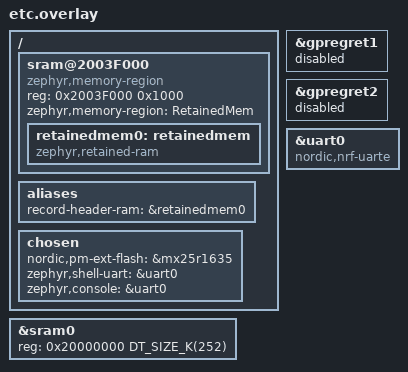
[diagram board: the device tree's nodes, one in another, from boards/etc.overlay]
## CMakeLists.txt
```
# SPDX-License-Identifier: Apache-2.0

cmake_minimum_required(VERSION 3.20.0)

find_package(Zephyr REQUIRED HINTS $ENV{ZEPHYR_BASE})
project(etc-retain)

FILE(GLOB app_sources src/*.c)
target_sources(app PRIVATE ${app_sources})
```

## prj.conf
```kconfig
CONFIG_STDOUT_CONSOLE=y
CONFIG_LOG=y
CONFIG_LOG_BUFFER_SIZE=4096
CONFIG_SERIAL=y

# Retain memory
CONFIG_RETAINED_MEM=y
CONFIG_RETAINED_MEM_NRF_GPREGRET=n
CONFIG_SHELL=y
```

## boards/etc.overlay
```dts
/ {
	sram@2003F000 {
		compatible = "zephyr,memory-region", "mmio-sram";
		reg = <0x2003F000 0x1000>;
		zephyr,memory-region = "RetainedMem";
		status = "okay";

		retainedmem0: retainedmem {
			compatible = "zephyr,retained-ram";
			status = "okay";
	        };
        };

	aliases {
		record-header-ram = &retainedmem0;
	};
};

&gpregret1 {
	status = "disabled";
};

&gpregret2 {
	status = "disabled";
};

&sram0 {
	reg = <0x20000000 DT_SIZE_K(252)>;
};

/ {
	chosen {
		nordic,pm-ext-flash = &mx25r1635;
		zephyr,shell-uart = &uart0;
		zephyr,console = &uart0;
	};
};

&uart0 {
	compatible = "nordic,nrf-uarte";
	status = "okay";
};
```

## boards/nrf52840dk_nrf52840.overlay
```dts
/ {
	sram@2003F000 {
		compatible = "zephyr,memory-region", "mmio-sram";
		reg = <0x2003F000 0x1000>;
		zephyr,memory-region = "RetainedMem";
		status = "okay";

		retainedmem0: retainedmem {
			compatible = "zephyr,retained-ram";
			status = "okay";
	        };
        };

	aliases {
		record-header-ram = &retainedmem0;
	};
};

&gpregret1 {
	status = "disabled";
};

&gpregret2 {
	status = "disabled";
};

&sram0 {
	reg = <0x20000000 DT_SIZE_K(252)>;
};
```

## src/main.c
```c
#include <stdio.h>
#include <string.h>
#include <zephyr/device.h>
#include <zephyr/drivers/uart.h>
#include <zephyr/drivers/gpio.h>
#include <zephyr/kernel.h>
#include <zephyr/usb/usb_device.h>
#include <zephyr/logging/log.h>
#include <zephyr/drivers/retained_mem.h>
#include <zephyr/shell/shell.h>
LOG_MODULE_REGISTER(main, LOG_LEVEL_INF);

#include "etc_device.h"
#include "etc_device_record.h"

int main(void)
{
	etc_device_record_init();
	etc_device_init();
	return 0;
}

static int cmd_write_record(const struct shell *shell, size_t argc, char **argv)
{
	if (argc == 2) {
		int num_of_sample = atoi(argv[1]);
		for (int i = 0; i < num_of_sample; i++) {
			etc_device_write();
		}
	} else {
		shell_error(shell, "Invalid input parameter for generating record");
	}

	return 0;
}

static int cmd_read_record(const struct shell *shell, size_t argc, char **argv)
{
	if (argc == 2) {
		int num_of_sample = atoi(argv[1]);
		for (int i = 0; i < num_of_sample; i++) {
			etc_device_read();
		}
	}
	return 0;
}

static int cmd_report_record(const struct shell *shell, size_t argc, char **argv)
{
	etc_device_report(shell);
	return 0;
}

static int cmd_export_record(const struct shell *shell, size_t argc, char **argv)
{
	etc_device_export_old_structure(shell);
	return 0;
}

static int cmd_dump_record(const struct shell *shell, size_t argc, char **argv)
{
	uint8_t* record = etc_device_record_dump();
	shell_hexdump(shell, record, ETC_DEVICE_RECORD_BUF_SIZE);
	return 0;
}

static int cmd_dump_old_record(const struct shell *shell, size_t argc, char **argv)
{
	uint8_t* record = etc_device_dump();
	shell_hexdump(shell, record, MAX_RECORD_NO_OFFSET_ID);
	return 0;
}

static int cmd_clean_record(const struct shell *shell, size_t argc, char **argv)
{
	etc_device_record_clean_up();
	return 0;
}

SHELL_STATIC_SUBCMD_SET_CREATE(
	sub_record,
	SHELL_CMD(write, NULL, "Init", cmd_write_record),
	SHELL_CMD(read, NULL, "Read", cmd_read_record),
	SHELL_CMD(report, NULL, "Report", cmd_report_record),
	SHELL_CMD(export, NULL, "Export", cmd_export_record),
	SHELL_CMD(dump, NULL, "Dump", cmd_dump_record),
	SHELL_CMD(dump_old, NULL, "Dump Old", cmd_dump_old_record),
	SHELL_CMD(clean, NULL, "Clean", cmd_clean_record),
	SHELL_SUBCMD_SET_END);
SHELL_CMD_REGISTER(record, &sub_record, "ETC Record Management", NULL);
```

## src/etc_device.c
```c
#include <stdio.h>
#include <string.h>
#include <zephyr/device.h>
#include <zephyr/logging/log.h>
#include <zephyr/shell/shell.h>
LOG_MODULE_REGISTER(etc_device, LOG_LEVEL_DBG);

#include "etc_device.h"
#include "etc_device_record.h"
#define OLD_RECORD 1

struct etc_device_record_table *etc_device_record_table = &etc_device_record.record_stat;

uint8_t record_header[MAX_RECORD_ID];
static uint16_t ram_nack_record_id;

void etc_device_init(void) {
	memset(record_header, 0, MAX_RECORD_ID);
	ram_nack_record_id = 0;
}

static struct etc_device_record_index etc_device_get_next_index(void)
{
	if (etc_device_record_table->newest.element_idx < ETC_RECORD_MAX_PER_SECTOR - 1) {
		etc_device_record_table->newest.element_idx += 1;
	} else {
		etc_device_record_table->newest.element_idx = 0;
		if (etc_device_record_table->newest.sector_idx < ETC_RECORD_MAX_SECTOR - 1) {
			etc_device_record_table->newest.sector_idx += 1;
		} else {
			etc_device_record_table->newest.sector_idx = 0;
		}
	}

	if (etc_device_record_table->total < ETC_RECORD_MAX_RECORD) {
		etc_device_record_table->oldest.element_idx = 0;
		etc_device_record_table->oldest.sector_idx = 0;
		etc_device_record_table->total += 1;
	} else {
		if (etc_device_record_table->oldest.element_idx < ETC_RECORD_MAX_PER_SECTOR - 1) {
			etc_device_record_table->oldest.element_idx += 1;
		} else {
			etc_device_record_table->oldest.element_idx = 0;
			if (etc_device_record_table->oldest.sector_idx < ETC_RECORD_MAX_SECTOR - 1) {
				etc_device_record_table->oldest.sector_idx += 1;
			} else {
				etc_device_record_table->oldest.sector_idx = 0;
			}
		}
	}

	return etc_device_record_table->newest;
}

struct etc_device_record_index etc_device_write(void) {
	struct etc_device_record_index record_index;
	if (etc_device_record_table->total == 0) {
		record_index = etc_device_record_table->newest;
		etc_device_record_table->total += 1;
	} else {
		record_index = etc_device_get_next_index();
	}

	uint16_t record_id = record_index.sector_idx * ETC_RECORD_MAX_PER_SECTOR +
			     record_index.element_idx;
	#if OLD_RECORD
	record_header[ETC_RECORD_ID_HEADER(record_id)] = 0U;
	#else
	etc_device_record_set_nack(record_id);
	#endif
	etc_device_record_save_stat();
	return record_index;
}

int etc_device_find_nack(void)
{
	int rc = 0;
	int newest_id = etc_device_record_table->newest.sector_idx * ETC_RECORD_MAX_PER_SECTOR +
			etc_device_record_table->newest.element_idx + ETC_RECORD_HEADER;
	int oldest_id = etc_device_record_table->oldest.sector_idx * ETC_RECORD_MAX_PER_SECTOR +
			etc_device_record_table->oldest.element_idx + ETC_RECORD_HEADER;
	uint16_t max_id = ETC_RECORD_MAX_SECTOR * ETC_RECORD_MAX_PER_SECTOR + ETC_RECORD_HEADER - 1;
	uint16_t min_id = ETC_RECORD_HEADER;
	uint16_t last_id = ram_nack_record_id;
	uint16_t check_id = 0;
	bool find_next = false;

	if (last_id == newest_id) {
		return 0;
	}

	check_id = last_id == 0 ? oldest_id : last_id + 1;
	if (check_id > max_id) {
		check_id = min_id;
	}

next_id:
	// LOG_DBG("Last ID %u - Check ID %d - New ID %d", last_id, check_id, newest_id);

	if (record_header[check_id] == 0) {
		rc = check_id;
	} else {
		find_next = true;
	}

	if (find_next) {
		find_next = false;
		if (newest_id != check_id) {
			/* Increase the ram_nack_record_id */
			check_id += 1;
			if (check_id > max_id) {
				check_id = min_id;
			}
			goto next_id;
		} 
	}

	return rc;
}

void etc_device_read(void) {
	int rc = etc_device_find_nack();
	if (rc == 0) {
		LOG_WRN("No more NACK");
		return;
	}
	// LOG_DBG("Record %d", rc);
	ram_nack_record_id = rc;
	record_header[rc] = 1U;
}

uint16_t etc_device_get_num_ack(void) {
	uint16_t oldest_id = ETC_RECORD_MAX_PER_SECTOR * etc_device_record_table->oldest.sector_idx +
			  etc_device_record_table->oldest.element_idx + ETC_RECORD_HEADER;
	uint16_t newest_id = ETC_RECORD_MAX_PER_SECTOR * etc_device_record_table->newest.sector_idx +
			  etc_device_record_table->newest.element_idx + ETC_RECORD_HEADER;
	uint16_t max_id = ETC_RECORD_MAX_SECTOR * ETC_RECORD_MAX_PER_SECTOR + ETC_RECORD_HEADER - 1;
	uint16_t min_id = ETC_RECORD_HEADER;
	uint16_t total_record = etc_device_record_table->total;
	uint16_t count = 0;
	uint16_t current_record = newest_id;
	uint16_t ack = 0;
	while (count < total_record) {
		if (record_header[current_record] == 1) {
			// LOG_DBG("Record %d", current_record);
			ack += 1;
		}

		if (current_record == oldest_id) {
			break;
		}

		current_record--;
		
		if (current_record < min_id) {
			current_record = max_id;
		}

		count++;
	}
	return ack;
}

void etc_device_report(const struct shell *shell) {
	uint16_t ack = etc_device_get_num_ack();
	uint16_t oldest_id = ETC_RECORD_MAX_PER_SECTOR  * etc_device_record_table->oldest.sector_idx +
			  etc_device_record_table->oldest.element_idx + ETC_RECORD_HEADER;
	uint16_t newest_id = ETC_RECORD_MAX_PER_SECTOR  * etc_device_record_table->newest.sector_idx +
			  etc_device_record_table->newest.element_idx + ETC_RECORD_HEADER;
	shell_print(shell, "%d %d %d %d %d", MAX_RECORD_ID, MIN_RECORD_ID, ETC_RECORD_MAX_SECTOR, ETC_RECORD_MAX_PER_SECTOR , ETC_RECORD_HEADER);
	shell_print(shell, "%d %d - %d %d", etc_device_record_table->oldest.sector_idx, etc_device_record_table->oldest.element_idx,
		etc_device_record_table->newest.sector_idx, etc_device_record_table->newest.element_idx);
	shell_print(shell, "Old ID %d (%d) - New %d (%d)", oldest_id, ETC_RECORD_ID(oldest_id), newest_id, ETC_RECORD_ID(newest_id));
	shell_print(shell, "Total %d - ACK %d - NACK %d", etc_device_record_table->total, ack, etc_device_record_table->total - ack);
}

void etc_device_export_old_structure(const struct shell *shell) {
	uint16_t oldest_id = ETC_RECORD_MAX_PER_SECTOR * etc_device_record_table->oldest.sector_idx +
			  etc_device_record_table->oldest.element_idx + ETC_RECORD_HEADER;
	uint16_t newest_id = ETC_RECORD_MAX_PER_SECTOR * etc_device_record_table->newest.sector_idx +
			  etc_device_record_table->newest.element_idx + ETC_RECORD_HEADER;
	uint16_t max_id = ETC_RECORD_MAX_SECTOR * ETC_RECORD_MAX_PER_SECTOR + ETC_RECORD_HEADER - 1;
	uint16_t min_id = ETC_RECORD_HEADER;
	uint16_t total_record = etc_device_record_table->total;
	uint16_t count = 0;
	uint16_t current_record = newest_id;
	int rc = 0;
	uint16_t ack_cnt = 0;
	shell_print(shell, "Export from old structure");
	while (count < total_record) {
		if (record_header[current_record] == 1) {
			etc_device_record_set_ack(ETC_RECORD_ID(current_record));
			ack_cnt += 1;
		} else {
			etc_device_record_set_nack(ETC_RECORD_ID(current_record));
		}

		if (current_record == oldest_id) {
			break;
		}

		current_record--;
		
		if (current_record < min_id) {
			current_record = max_id;
		}

		count++;
	}

	shell_print(shell, "Export success %d %d %d %d %d", count, ETC_RECORD_ID(current_record), oldest_id, newest_id, ack_cnt);
}

uint8_t* etc_device_dump(void) {
	return &record_header[ETC_RECORD_HEADER];
}
```

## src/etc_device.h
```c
#ifndef ETC_DEVICE_H_
#define ETC_DEVICE_H_

#include <zephyr/shell/shell.h>

#include "etc_device_record.h"

#define ETC_CONFIG_TYPE_SIZE   (32)
#define ETC_DEVICE_RECORD_SIZE (36)
#define ETC_DEVICE_NUM_SENSOR  (6) // 5 temperatures + 1 humidity
#define ETC_DEVICE_LOGGER_LORA_SYNC_CLOUD_OFFSET_HOUR (16)

/**
 * @brief Define a flash sector size based on HW
 *
 */
#define ETC_FLASH_SECTOR_SIZE	  (4096)
/**
 * @brief Define maximum record per sector
 */
#define ETC_RECORD_MAX_PER_SECTOR ((int)(ETC_FLASH_SECTOR_SIZE) / (ETC_DEVICE_RECORD_SIZE))
/**
 * @brief Maximum record in requirement
 */
#define ETC_RECORD_MAX_RECORD	  (90 * 24 * 4)
/**
 * @brief Max sector = round(fit sector + 1 free sector for swap) (ETC_RECORD_MAX_RECORD /
 * ETC_RECORD_MAX_PER_SECTOR) + 1
 */
#define ETC_RECORD_MAX_SECTOR	  ((int)((ETC_RECORD_MAX_RECORD) / (ETC_RECORD_MAX_PER_SECTOR)) + 1)

#define ETC_RECORD_ID_HEADER(x) (x + ETC_RECORD_HEADER)
#define ETC_RECORD_ID(x) (x - ETC_RECORD_HEADER)

#define MAX_RECORD_ID ( ETC_RECORD_MAX_SECTOR * ETC_RECORD_MAX_PER_SECTOR + ETC_RECORD_HEADER - 1)
#define MIN_RECORD_ID ( ETC_RECORD_HEADER )
#define MAX_RECORD_NO_OFFSET_ID ( ETC_RECORD_MAX_SECTOR * ETC_RECORD_MAX_PER_SECTOR - 1) 
#define MIN_RECORD_NO_OFFSET_ID ( 0 )

enum etc_setting_id {
	ETC_RECORD_HEADER = 0x1000,
};

void etc_device_init(void);
struct etc_device_record_index etc_device_write(void);
void etc_device_read(void);
void etc_device_report(const struct shell *shell);
void etc_device_export_old_structure(const struct shell *shell);
uint8_t* etc_device_dump(void);
#endif /* ETC_DEVICE_H_ */
```

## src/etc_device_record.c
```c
#include <stdio.h>
#include <string.h>
#include <zephyr/device.h>
#include <zephyr/logging/log.h>
#include <zephyr/drivers/retained_mem.h>
#include <zephyr/shell/shell.h>
LOG_MODULE_REGISTER(etc_device_record, LOG_LEVEL_DBG);

#include "etc_device_record.h"

const static struct device *retained_ram_dev =	DEVICE_DT_GET(DT_ALIAS(record_header_ram));

struct etc_device_record_data etc_device_record;
struct etc_device_record_data* pRecord = &etc_device_record;

#define RECORD_ARRAY_OFFSET(x) (offsetof(struct etc_device_record_data, record_bits) + x)
#define RECORD_FLAG_OFFSET offsetof(struct etc_device_record_data, record_sync_flag)
#define RECORD_STAT_OFFSET offsetof(struct etc_device_record_data, record_stat)

static int etc_device_record_get_ack_status(int record_id) {
	uint16_t byte_pos = record_id / 8;
	uint8_t bit_pos = record_id % 8;
	uint8_t byte_status = pRecord->record_bits[byte_pos];
	return (byte_status >> bit_pos) & 0x01;
}

static void etc_device_record_set_ack_status(int record_id, int status) {
	uint16_t byte_pos = record_id / 8;
	uint8_t bit_pos = record_id % 8;
	uint8_t* byte_status = &pRecord->record_bits[byte_pos];
	if (status == 0) {
		*byte_status &= ~(1 << bit_pos); 
	} else {
		*byte_status |= (1 << bit_pos);
	}
}

void etc_device_record_init(void) {
	int rc = retained_mem_read(retained_ram_dev, 0, (uint8_t*)pRecord, 
		sizeof(struct etc_device_record_data));

	if ((rc) || (pRecord->record_sync_flag != ETC_DEVICE_RECORD_FLAG)) {
		/* Clean up the memory RAM in no-init region */
		retained_mem_clear(retained_ram_dev);
		/* Clean up the record in app RAM */
		memset(pRecord, 0, sizeof(struct etc_device_record_data));
		pRecord->record_sync_flag = ETC_DEVICE_RECORD_FLAG;
		pRecord->record_stat.newest.sector_idx = 0;
		pRecord->record_stat.oldest.sector_idx = 0;
		pRecord->record_stat.newest.element_idx = 0;
		pRecord->record_stat.oldest.element_idx = 0;
		pRecord->record_stat.total = 0;
		/* Save it */
		rc = retained_mem_write(retained_ram_dev, RECORD_FLAG_OFFSET, 
			(uint8_t*)&pRecord->record_sync_flag, sizeof(pRecord->record_sync_flag));
		if (rc) {
			printk("Failed to write data - err %d\n", rc);
		}
	} else {
		printk("Record is ready\n");
	}
}

int etc_device_record_get_ack(int record_id) {
	return etc_device_record_get_ack_status(record_id);
}

void etc_device_record_set_ack(int record_id) {
	etc_device_record_set_ack_status(record_id, 1);
	uint16_t byte_position = record_id / 8;
	int rc = retained_mem_write(retained_ram_dev, RECORD_ARRAY_OFFSET(byte_position), 
		(uint8_t*)&pRecord->record_bits[byte_position], sizeof(uint8_t));
	if (rc) {
		LOG_ERR("Failed to write data - err %d", rc);
	}
}

void etc_device_record_set_nack(int record_id) {
	etc_device_record_set_ack_status(record_id, 0);
	uint16_t byte_position = record_id / 8;
	int rc = retained_mem_write(retained_ram_dev, RECORD_ARRAY_OFFSET(byte_position), 
		(uint8_t*)&pRecord->record_bits[byte_position], sizeof(uint8_t));
	if (rc) {
		LOG_ERR("Failed to write data - err %d", rc);
	}
}

uint8_t* etc_device_record_dump(void) {
	return pRecord->record_bits;
}

void etc_device_record_clean_up(void) {
	retained_mem_clear(retained_ram_dev);
	memset(pRecord, 0, sizeof(struct etc_device_record_data));
	pRecord->record_sync_flag = ETC_DEVICE_RECORD_FLAG;
	int rc = retained_mem_write(retained_ram_dev, RECORD_FLAG_OFFSET, 
		(uint8_t*)&pRecord->record_sync_flag, sizeof(pRecord->record_sync_flag));
	if (rc) {
		LOG_ERR("Failed to write data - err %d", rc);
	}
}

void etc_device_record_save_stat(void) {
	int rc = retained_mem_write(retained_ram_dev, RECORD_STAT_OFFSET, 
		(uint8_t*)&pRecord->record_stat, sizeof(pRecord->record_stat));
	if (rc) {
		LOG_ERR("Failed to write data - err %d", rc);
	}
}
```

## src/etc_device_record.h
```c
#ifndef ETC_DEVICE_RECORD_H_
#define ETC_DEVICE_RECORD_H_

#define ETC_DEVICE_RECORD_BUF_SIZE (1088)
#define ETC_DEVICE_RECORD_FLAG (0xCAFEBEEF)

struct etc_device_record_index { // Constant in flash until the index is override (exflash)
	uint8_t sector_idx;
	uint8_t element_idx;
};

struct etc_device_record_table {
	struct etc_device_record_index oldest;
	struct etc_device_record_index newest;
	uint16_t total;
};

struct etc_device_record_data {
	struct etc_device_record_table record_stat;
	/* Record bits array to store ACK/NACK data */
	uint8_t record_bits[ETC_DEVICE_RECORD_BUF_SIZE];
	/* Flag to determine data is synced */
	uint32_t record_sync_flag;
};

extern struct etc_device_record_data etc_device_record;

void etc_device_record_init(void);
int  etc_device_record_get_ack(int record_id);
void etc_device_record_set_ack(int record_id);
void etc_device_record_set_nack(int record_id);
uint8_t* etc_device_record_dump(void);
void etc_device_record_clean_up(void);
void etc_device_record_save_stat(void);
#endif /* ETC_DEVICE_RECORD_H_ */
```
